AUTOSAR XML (schema 4-2-2)
package /ASW_COM_Package
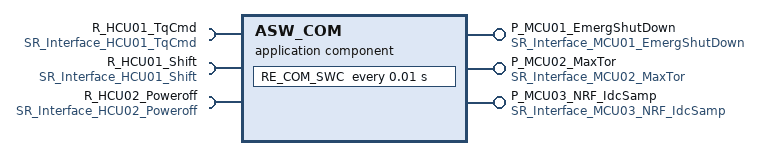
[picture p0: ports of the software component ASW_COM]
  application sw component type ASW_COM
    provide port P_MCU01_EmergShutDown: provided-interface=SR_Interface_MCU01_EmergShutDown
    provide port P_MCU02_MaxTor: provided-interface=SR_Interface_MCU02_MaxTor
    provide port P_MCU03_NRF_IdcSamp: provided-interface=SR_Interface_MCU03_NRF_IdcSamp
    require port R_HCU01_TqCmd: required-interface=SR_Interface_HCU01_TqCmd
    require port R_HCU01_Shift: required-interface=SR_Interface_HCU01_Shift
    require port R_HCU02_Poweroff: nonqueued-receiver-com-spec{data-element=DE_HCU02_Poweroff, alive-timeout=0.3}, required-interface=SR_Interface_HCU02_Poweroff
    behavior IB_ASW_COM
      timing event TE_RE_COM_SWC_10ms: start-on-event=RE_COM_SWC, period=0.01
      runnable RE_COM_SWC
        data-receive-point-by-arguments:
          access REC_HCU01_TqCmd: accessed-variable=R_HCU01_TqCmd.DE_HCU01_TqCmd
          access REC_HCU01_Shift: accessed-variable=R_HCU01_Shift.DE_HCU01_Shift
          access REC_HCU02_Poweroff: accessed-variable=R_HCU02_Poweroff.DE_HCU02_Poweroff
        data-send-points:
          access SEND_MCU01_EmergShutDown: accessed-variable=P_MCU01_EmergShutDown.DE_MCU01_EmergShutDown
          access SEND_MCU02_MaxTor: accessed-variable=P_MCU02_MaxTor.DE_MCU02_MaxTor
          access SEND_MCU03_NRF_IdcSamp: accessed-variable=P_MCU03_NRF_IdcSamp.DE_MCU03_NRF_IdcSamp
